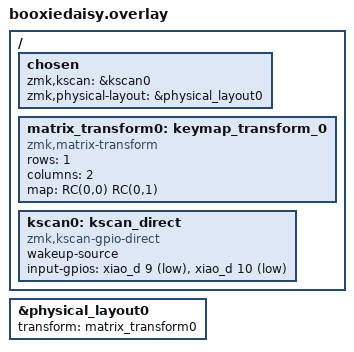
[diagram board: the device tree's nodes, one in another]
#include "booxiedaisy-layouts.dtsi"
#include <dt-bindings/zmk/matrix_transform.h>

&physical_layout0 {
    transform = <&matrix_transform0>;
};

/ {
    chosen {
        zmk,kscan = &kscan0;
        zmk,physical-layout = &physical_layout0;
    };

    matrix_transform0: keymap_transform_0 {
        compatible = "zmk,matrix-transform";
        rows = <1>;
        columns = <2>;
        map = <
            RC(0,0) RC(0,1)
        >;  
    };

    kscan0: kscan_direct {
        compatible = "zmk,kscan-gpio-direct";
        wakeup-source;
        input-gpios
            // vol+, switch between GND and d9
            = <&xiao_d 9 (GPIO_ACTIVE_LOW | GPIO_PULL_UP)>
            // vol-, switch between GND and d10
            , <&xiao_d 10 (GPIO_ACTIVE_LOW | GPIO_PULL_UP)>
            ;
    };
};
